AUTOSAR XML (schema 4-0-3)
package /ComponentTypes
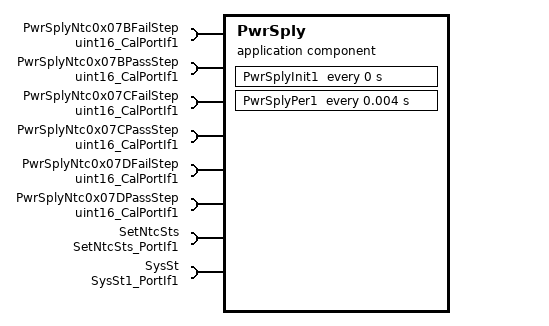
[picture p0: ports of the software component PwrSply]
  application sw component type PwrSply
    8 x require port:
      PwrSplyNtc0x07BFailStep: parameter-require-com-spec{init-value=13106, parameter=Val}, required-interface=uint16_CalPortIf1
      PwrSplyNtc0x07BPassStep: parameter-require-com-spec{init-value=13106, parameter=Val}, required-interface=uint16_CalPortIf1
      PwrSplyNtc0x07CFailStep: parameter-require-com-spec{init-value=13106, parameter=Val}, required-interface=uint16_CalPortIf1
      PwrSplyNtc0x07CPassStep: parameter-require-com-spec{init-value=13106, parameter=Val}, required-interface=uint16_CalPortIf1
      PwrSplyNtc0x07DFailStep: parameter-require-com-spec{init-value=13106, parameter=Val}, required-interface=uint16_CalPortIf1
      PwrSplyNtc0x07DPassStep: parameter-require-com-spec{init-value=13106, parameter=Val}, required-interface=uint16_CalPortIf1
      SetNtcSts: required-interface=SetNtcSts_PortIf1
      SysSt: nonqueued-receiver-com-spec{data-element=Val, filter=data-filter-type=ALWAYS, init-value=3}, required-interface=SysSt1_PortIf1
    behavior PwrSply_InternalBehavior
      ar-typed-per-instance-memorys:
        data PwrSplyReadWrOrderFlg1: sw-calibration-access=READ-ONLY, type=boolean
        data PwrSplyReadWrOrderFlg2: sw-calibration-access=READ-ONLY, type=boolean
        data PwrSplyStrtUpSelfTestCmpl: sw-calibration-access=READ-ONLY, type=boolean
      timing event PwrSply_InitEvent: start-on-event=PwrSplyInit1, period=0
      timing event TMT_PwrSplyPer1: start-on-event=PwrSplyPer1, period=0.004
      runnable PwrSplyInit1
      runnable PwrSplyPer1
        data-receive-point-by-arguments:
          access REC_SysSt_Val: accessed-variable=SysSt.Val
        sync call SC_SetNtcSts_Oper: operation=SetNtcSts.Oper, timeout=0
  swc implementation PwrSply_Implementation: behavior=PwrSply_InternalBehavior
    code-descriptors:
      code Default: artifact-descriptors=autosar-engineering-object={short-label=Default, category=SWSRC}
